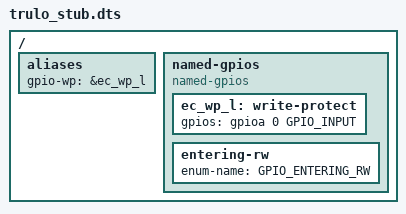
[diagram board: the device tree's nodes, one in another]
/* Copyright 2024 The ChromiumOS Authors
 * Use of this source code is governed by a BSD-style license that can be
 * found in the LICENSE file.
 */

 / {
	aliases {
		gpio-wp = &ec_wp_l;
	};

	named-gpios {
		compatible = "named-gpios";

		ec_wp_l: write-protect {
			gpios = <&gpioa 0 GPIO_INPUT>;
		};
		/* unimplemented GPIOs */
		entering-rw {
			enum-name = "GPIO_ENTERING_RW";
		};
	};
};
